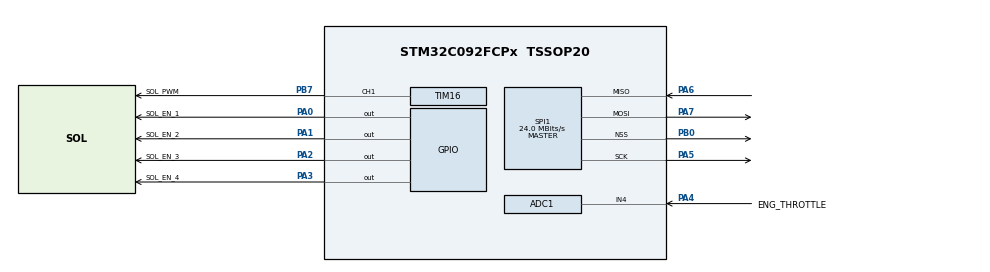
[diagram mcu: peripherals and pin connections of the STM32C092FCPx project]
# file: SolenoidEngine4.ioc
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ADC1.ContinuousConvMode=ENABLE
ADC1.EOCSelection=ADC_EOC_SEQ_CONV
ADC1.NbrOfConversionFlag=0
ADC1.Overrun=ADC_OVR_DATA_OVERWRITTEN
ADC1.OversamplingMode=ENABLE
ADC1.Ratio=ADC_OVERSAMPLING_RATIO_256
ADC1.RightBitShift=ADC_RIGHTBITSHIFT_8
ADC1.SamplingTimeCommon1=ADC_SAMPLETIME_160CYCLES_5
ADC1.SelectedChannel=ADC_CHANNEL_4|ADC_CHANNEL_VREFINT
ADC1.master=1
Dma.ADC1.0.Direction=DMA_PERIPH_TO_MEMORY
Dma.ADC1.0.EventEnable=DISABLE
Dma.ADC1.0.Instance=DMA1_Channel1
Dma.ADC1.0.MemDataAlignment=DMA_MDATAALIGN_HALFWORD
Dma.ADC1.0.MemInc=DMA_MINC_ENABLE
Dma.ADC1.0.Mode=DMA_NORMAL
Dma.ADC1.0.PeriphDataAlignment=DMA_PDATAALIGN_HALFWORD
Dma.ADC1.0.PeriphInc=DMA_PINC_DISABLE
Dma.ADC1.0.Polarity=HAL_DMAMUX_REQ_GEN_RISING
Dma.ADC1.0.Priority=DMA_PRIORITY_LOW
Dma.ADC1.0.RequestNumber=1
Dma.ADC1.0.SignalID=NONE
Dma.ADC1.0.SyncEnable=DISABLE
Dma.ADC1.0.SyncPolarity=HAL_DMAMUX_SYNC_NO_EVENT
Dma.ADC1.0.SyncRequestNumber=1
Dma.ADC1.0.SyncSignalID=NONE
Dma.Request0=ADC1
Mcu.Family=STM32C0
Mcu.Name=STM32C092FCPx
Mcu.Package=TSSOP20
NVIC.ADC1_IRQn=true\:0\:0\:false\:false\:true\:true\:true\:true
NVIC.DMA1_Channel1_IRQn=true\:0\:0\:false\:false\:true\:false\:true\:true
NVIC.TIM17_IRQn=true\:0\:0\:false\:false\:true\:true\:true\:true
PA0.GPIO_Label=SOL_EN_1
PA0.Signal=GPIO_Output
PA1.GPIO_Label=SOL_EN_2
PA1.Signal=GPIO_Output
PA13.Mode=Serial_Wire
PA13.Signal=DEBUG_SWDIO
PA14-BOOT0.Mode=Serial_Wire
PA14-BOOT0.Signal=DEBUG_SWCLK
PA14-BOOT0__PA15.StandardMode=true
PA2.GPIO_Label=SOL_EN_3
PA2.Signal=GPIO_Output
PA3.GPIO_Label=SOL_EN_4
PA3.Signal=GPIO_Output
PA4.GPIO_Label=ENG_THROTTLE
PA4.Mode=IN4
PA4.Signal=ADC1_IN4
PA5.Mode=Full_Duplex_Master
PA5.Signal=SPI1_SCK
PA6.Mode=Full_Duplex_Master
PA6.Signal=SPI1_MISO
PA7.Mode=Full_Duplex_Master
PA7.Signal=SPI1_MOSI
PB0.Mode=NSS_Signal_Hard_Output
PB0.Signal=SPI1_NSS
PB0__PB1__PB2__PA8.StandardMode=true
PB3__PB4__PB5__PB6.StandardMode=true
PB7.GPIO_Label=SOL_PWM
PB7.Signal=S_TIM16_CH1
PB7__PB8.StandardMode=true
ProjectManager.HeapSize=0x200
ProjectManager.StackSize=0x400
ProjectManager.TargetToolchain=CMake
RCC.ADCFreq_Value=48000000
RCC.AHBFreq_Value=48000000
RCC.CortexFreq_Value=48000000
RCC.EXTERNAL_CLOCK_VALUE=12288000
RCC.HCLKFreq_Value=48000000
RCC.HSE_VALUE=8000000
RCC.HSISYSCLKDivider=RCC_HSI_DIV1
RCC.HSI_VALUE=48000000
RCC.LSE_VALUE=32768
RCC.SYSCLKFreq_VALUE=48000000
SH.S_TIM16_CH1.0=TIM16_CH1,PWM Generation1 CH1
SPI1.CalculateBaudRate=24.0 MBits/s
SPI1.DataSize=SPI_DATASIZE_16BIT
SPI1.Direction=SPI_DIRECTION_2LINES
SPI1.Mode=SPI_MODE_MASTER
SPI1.VirtualNSS=VM_NSSHARD
SPI1.VirtualType=VM_MASTER
TIM16.Channel=TIM_CHANNEL_1
TIM17.Period=999
TIM17.Prescaler=47
VP_ADC1_Vref_Input.Mode=IN-Vrefint
VP_TIM16_VS_ClockSourceINT.Mode=Enable_Timer
VP_TIM17_VS_ClockSourceINT.Mode=Enable_Timer
board=custom

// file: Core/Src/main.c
/* USER CODE BEGIN Header */
/**
  ******************************************************************************
  * @file           : main.c
  * @brief          : Main program body
  ******************************************************************************
  * @attention
  *
  * Copyright (c) 2026 STMicroelectronics.
  * All rights reserved.
  *
  * This software is licensed under terms that can be found in the LICENSE file
  * in the root directory of this software component.
  * If no LICENSE file comes with this software, it is provided AS-IS.
  *
  ******************************************************************************
  */
/* USER CODE END Header */
#include "main.h"

ADC_HandleTypeDef hadc1;
DMA_HandleTypeDef hdma_adc1;

SPI_HandleTypeDef hspi1;

TIM_HandleTypeDef htim16;
TIM_HandleTypeDef htim17;

void SystemClock_Config(void);
static void MX_GPIO_Init(void);
static void MX_DMA_Init(void);
static void MX_ADC1_Init(void);
static void MX_SPI1_Init(void);
static void MX_TIM16_Init(void);
static void MX_TIM17_Init(void);

/* USER CODE BEGIN 0 */

void main_SolenoidEngine4(
  ADC_HandleTypeDef *h_eng_throttle,
  SPI_HandleTypeDef *h_resolver,
  TIM_HandleTypeDef *h_pwm,
  TIM_HandleTypeDef *h_1ms
);

/* USER CODE END 0 */

int main(void)
{

  /* MCU Configuration--------------------------------------------------------*/

  /* Reset of all peripherals, Initializes the Flash interface and the Systick. */
  HAL_Init();

  /* Configure the system clock */
  SystemClock_Config();

  /* Initialize all configured peripherals */
  MX_GPIO_Init();
  MX_DMA_Init();
  MX_ADC1_Init();
  MX_SPI1_Init();
  MX_TIM16_Init();
  MX_TIM17_Init();
  /* USER CODE BEGIN 2 */

  main_SolenoidEngine4(&hadc1, &hspi1, &htim16, &htim17);

  /* USER CODE END 2 */

  /* Infinite loop */
  while (1)
  {

  }
}

void SystemClock_Config(void)
{
  RCC_OscInitTypeDef RCC_OscInitStruct = {0};
  RCC_ClkInitTypeDef RCC_ClkInitStruct = {0};

  __HAL_FLASH_SET_LATENCY(FLASH_LATENCY_1);

  /** Initializes the RCC Oscillators according to the specified parameters
  * in the RCC_OscInitTypeDef structure.
  */
  RCC_OscInitStruct.OscillatorType = RCC_OSCILLATORTYPE_HSI;
  RCC_OscInitStruct.HSIState = RCC_HSI_ON;
  RCC_OscInitStruct.HSIDiv = RCC_HSI_DIV1;
  RCC_OscInitStruct.HSICalibrationValue = RCC_HSICALIBRATION_DEFAULT;
  if (HAL_RCC_OscConfig(&RCC_OscInitStruct) != HAL_OK)
  {
    Error_Handler();
  }

  /** Initializes the CPU, AHB and APB buses clocks
  */
  RCC_ClkInitStruct.ClockType = RCC_CLOCKTYPE_HCLK|RCC_CLOCKTYPE_SYSCLK
                              |RCC_CLOCKTYPE_PCLK1;
  RCC_ClkInitStruct.SYSCLKSource = RCC_SYSCLKSOURCE_HSI;
  RCC_ClkInitStruct.SYSCLKDivider = RCC_SYSCLK_DIV1;
  RCC_ClkInitStruct.AHBCLKDivider = RCC_HCLK_DIV1;
  RCC_ClkInitStruct.APB1CLKDivider = RCC_APB1_DIV1;

  if (HAL_RCC_ClockConfig(&RCC_ClkInitStruct, FLASH_LATENCY_1) != HAL_OK)
  {
    Error_Handler();
  }
}

static void MX_ADC1_Init(void)
{

  ADC_ChannelConfTypeDef sConfig = {0};

  /** Configure the global features of the ADC (Clock, Resolution, Data Alignment and number of conversion)
  */
  hadc1.Instance = ADC1;
  hadc1.Init.ClockPrescaler = ADC_CLOCK_SYNC_PCLK_DIV2;
  hadc1.Init.Resolution = ADC_RESOLUTION_12B;
  hadc1.Init.DataAlign = ADC_DATAALIGN_RIGHT;
  hadc1.Init.ScanConvMode = ADC_SCAN_SEQ_FIXED;
  hadc1.Init.EOCSelection = ADC_EOC_SEQ_CONV;
  hadc1.Init.LowPowerAutoWait = DISABLE;
  hadc1.Init.LowPowerAutoPowerOff = DISABLE;
  hadc1.Init.ContinuousConvMode = ENABLE;
  hadc1.Init.NbrOfConversion = 1;
  hadc1.Init.ExternalTrigConv = ADC_SOFTWARE_START;
  hadc1.Init.ExternalTrigConvEdge = ADC_EXTERNALTRIGCONVEDGE_NONE;
  hadc1.Init.DMAContinuousRequests = DISABLE;
  hadc1.Init.Overrun = ADC_OVR_DATA_OVERWRITTEN;
  hadc1.Init.SamplingTimeCommon1 = ADC_SAMPLETIME_160CYCLES_5;
  hadc1.Init.OversamplingMode = ENABLE;
  hadc1.Init.Oversampling.Ratio = ADC_OVERSAMPLING_RATIO_256;
  hadc1.Init.Oversampling.RightBitShift = ADC_RIGHTBITSHIFT_8;
  hadc1.Init.Oversampling.TriggeredMode = ADC_TRIGGEREDMODE_SINGLE_TRIGGER;
  hadc1.Init.TriggerFrequencyMode = ADC_TRIGGER_FREQ_HIGH;
  if (HAL_ADC_Init(&hadc1) != HAL_OK)
  {
    Error_Handler();
  }

  /** Configure Regular Channel
  */
  sConfig.Channel = ADC_CHANNEL_4;
  sConfig.Rank = ADC_RANK_CHANNEL_NUMBER;
  if (HAL_ADC_ConfigChannel(&hadc1, &sConfig) != HAL_OK)
  {
    Error_Handler();
  }

  /** Configure Regular Channel
  */
  sConfig.Channel = ADC_CHANNEL_VREFINT;
  if (HAL_ADC_ConfigChannel(&hadc1, &sConfig) != HAL_OK)
  {
    Error_Handler();
  }

}

static void MX_SPI1_Init(void)
{

  /* SPI1 parameter configuration*/
  hspi1.Instance = SPI1;
  hspi1.Init.Mode = SPI_MODE_MASTER;
  hspi1.Init.Direction = SPI_DIRECTION_2LINES;
  hspi1.Init.DataSize = SPI_DATASIZE_16BIT;
  hspi1.Init.CLKPolarity = SPI_POLARITY_LOW;
  hspi1.Init.CLKPhase = SPI_PHASE_1EDGE;
  hspi1.Init.NSS = SPI_NSS_HARD_OUTPUT;
  hspi1.Init.BaudRatePrescaler = SPI_BAUDRATEPRESCALER_2;
  hspi1.Init.FirstBit = SPI_FIRSTBIT_MSB;
  hspi1.Init.TIMode = SPI_TIMODE_DISABLE;
  hspi1.Init.CRCCalculation = SPI_CRCCALCULATION_DISABLE;
  hspi1.Init.CRCPolynomial = 7;
  hspi1.Init.CRCLength = SPI_CRC_LENGTH_DATASIZE;
  hspi1.Init.NSSPMode = SPI_NSS_PULSE_ENABLE;
  if (HAL_SPI_Init(&hspi1) != HAL_OK)
  {
    Error_Handler();
  }

}

static void MX_TIM16_Init(void)
{

  TIM_OC_InitTypeDef sConfigOC = {0};
  TIM_BreakDeadTimeConfigTypeDef sBreakDeadTimeConfig = {0};

  htim16.Instance = TIM16;
  htim16.Init.Prescaler = 0;
  htim16.Init.CounterMode = TIM_COUNTERMODE_UP;
  htim16.Init.Period = 65535;
  htim16.Init.ClockDivision = TIM_CLOCKDIVISION_DIV1;
  htim16.Init.RepetitionCounter = 0;
  htim16.Init.AutoReloadPreload = TIM_AUTORELOAD_PRELOAD_DISABLE;
  if (HAL_TIM_Base_Init(&htim16) != HAL_OK)
  {
    Error_Handler();
  }
  if (HAL_TIM_PWM_Init(&htim16) != HAL_OK)
  {
    Error_Handler();
  }
  sConfigOC.OCMode = TIM_OCMODE_PWM1;
  sConfigOC.Pulse = 0;
  sConfigOC.OCPolarity = TIM_OCPOLARITY_HIGH;
  sConfigOC.OCNPolarity = TIM_OCNPOLARITY_HIGH;
  sConfigOC.OCFastMode = TIM_OCFAST_DISABLE;
  sConfigOC.OCIdleState = TIM_OCIDLESTATE_RESET;
  sConfigOC.OCNIdleState = TIM_OCNIDLESTATE_RESET;
  if (HAL_TIM_PWM_ConfigChannel(&htim16, &sConfigOC, TIM_CHANNEL_1) != HAL_OK)
  {
    Error_Handler();
  }
  sBreakDeadTimeConfig.OffStateRunMode = TIM_OSSR_DISABLE;
  sBreakDeadTimeConfig.OffStateIDLEMode = TIM_OSSI_DISABLE;
  sBreakDeadTimeConfig.LockLevel = TIM_LOCKLEVEL_OFF;
  sBreakDeadTimeConfig.DeadTime = 0;
  sBreakDeadTimeConfig.BreakState = TIM_BREAK_DISABLE;
  sBreakDeadTimeConfig.BreakPolarity = TIM_BREAKPOLARITY_HIGH;
  sBreakDeadTimeConfig.BreakFilter = 0;
  sBreakDeadTimeConfig.AutomaticOutput = TIM_AUTOMATICOUTPUT_DISABLE;
  if (HAL_TIMEx_ConfigBreakDeadTime(&htim16, &sBreakDeadTimeConfig) != HAL_OK)
  {
    Error_Handler();
  }
  HAL_TIM_MspPostInit(&htim16);

}

static void MX_TIM17_Init(void)
{

  htim17.Instance = TIM17;
  htim17.Init.Prescaler = 47;
  htim17.Init.CounterMode = TIM_COUNTERMODE_UP;
  htim17.Init.Period = 999;
  htim17.Init.ClockDivision = TIM_CLOCKDIVISION_DIV1;
  htim17.Init.RepetitionCounter = 0;
  htim17.Init.AutoReloadPreload = TIM_AUTORELOAD_PRELOAD_DISABLE;
  if (HAL_TIM_Base_Init(&htim17) != HAL_OK)
  {
    Error_Handler();
  }

}

static void MX_DMA_Init(void)
{

  /* DMA controller clock enable */
  __HAL_RCC_DMA1_CLK_ENABLE();

  /* DMA interrupt init */
  /* DMA1_Channel1_IRQn interrupt configuration */
  HAL_NVIC_SetPriority(DMA1_Channel1_IRQn, 0, 0);
  HAL_NVIC_EnableIRQ(DMA1_Channel1_IRQn);

}

static void MX_GPIO_Init(void)
{
  GPIO_InitTypeDef GPIO_InitStruct = {0};

  /* GPIO Ports Clock Enable */
  __HAL_RCC_GPIOB_CLK_ENABLE();
  __HAL_RCC_GPIOA_CLK_ENABLE();

  /*Configure GPIO pin Output Level */
  HAL_GPIO_WritePin(GPIOA, SOL_EN_1_Pin|SOL_EN_2_Pin|SOL_EN_3_Pin|SOL_EN_4_Pin, GPIO_PIN_RESET);

  /*Configure GPIO pins : SOL_EN_1_Pin SOL_EN_2_Pin SOL_EN_3_Pin SOL_EN_4_Pin */
  GPIO_InitStruct.Pin = SOL_EN_1_Pin|SOL_EN_2_Pin|SOL_EN_3_Pin|SOL_EN_4_Pin;
  GPIO_InitStruct.Mode = GPIO_MODE_OUTPUT_PP;
  GPIO_InitStruct.Pull = GPIO_NOPULL;
  GPIO_InitStruct.Speed = GPIO_SPEED_FREQ_LOW;
  HAL_GPIO_Init(GPIOA, &GPIO_InitStruct);

}

void Error_Handler(void)
{
  __disable_irq();
  while (1)
  {
  }
}
